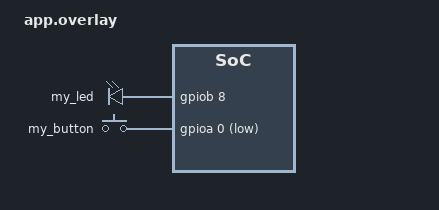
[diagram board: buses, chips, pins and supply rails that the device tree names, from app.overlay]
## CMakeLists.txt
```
cmake_minimum_required(VERSION 3.20.0)
set(BOARD stm32_min_dev/stm32f103xb CACHE STRING "Default board")

find_package(Zephyr REQUIRED HINTS $ENV{ZEPHYR_BASE})
project(zephyr-zl27arm)

list(APPEND CMAKE_MODULE_PATH ${ZEPHYR_BASE}/modules/nanopb)
include(nanopb)

target_include_directories(app PRIVATE src)
target_sources(app PRIVATE
        src/main_minimal.c
)
zephyr_nanopb_sources(app src/data.proto)
```

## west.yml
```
manifest:
  remotes:
    - name: zephyrproject-rtos
      url-base: https://github.com/zephyrproject-rtos

  projects:
    - name: zephyr
      remote: zephyrproject-rtos
      revision: v4.3.0
      import:
        name-allowlist:
          - cmsis_6
          - hal_stm32
          - segger
          - nanopb

  self:
    path: zephyr-zl27arm
```

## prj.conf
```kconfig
CONFIG_GPIO=y

CONFIG_NANOPB=y

# Debugging, tracing and logging settings
# (use the same for all projects)
CONFIG_STD_C23=y
#CONFIG_FPU=y
#CONFIG_ARM_MPU=y
#CONFIG_HW_STACK_PROTECTION=y

CONFIG_SERIAL=y
CONFIG_LOG=y
CONFIG_LOG_MODE_IMMEDIATE=y
CONFIG_LOG_DEFAULT_LEVEL=3

CONFIG_CONSOLE=y
CONFIG_LOG_BACKEND_RTT=y
CONFIG_USE_SEGGER_RTT=y

CONFIG_TRACING=y
CONFIG_TRACING_BACKEND_RAM=y
CONFIG_TRACING_GPIO=n
CONFIG_TRACING_SYSCALL=y
CONFIG_SEGGER_SYSTEMVIEW=y
CONFIG_SEGGER_SYSTEMVIEW_BOOT_ENABLE=n
CONFIG_SEGGER_SYSVIEW_RTT_BUFFER_SIZE=4096
CONFIG_SEGGER_SYSVIEW_POST_MORTEM_MODE=n

CONFIG_DEBUG=y
CONFIG_DEBUG_OPTIMIZATIONS=y
CONFIG_THREAD_ANALYZER=y
CONFIG_THREAD_NAME=y
```

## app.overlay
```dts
/ {
	aliases {
		led0 = &my_led;
		sw0 = &my_button;
	};

	leds {
		compatible = "gpio-leds";
		my_led: led_pb8 {
			gpios = <&gpiob 8 GPIO_ACTIVE_HIGH>;
		};
	};

	buttons {
		compatible = "gpio-keys";
		my_button: button_pa0 {
			gpios = <&gpioa 0 (GPIO_ACTIVE_LOW | GPIO_PULL_UP)>;
		};
	};
};
```

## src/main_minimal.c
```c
#include <zephyr/kernel.h>
#include <zephyr/drivers/gpio.h>
#include "zephyr/logging/log.h"

LOG_MODULE_REGISTER(main, LOG_LEVEL_INF);

static const struct gpio_dt_spec led =
    GPIO_DT_SPEC_GET(DT_ALIAS(led0), gpios);

static const struct gpio_dt_spec button =
    GPIO_DT_SPEC_GET(DT_ALIAS(sw0), gpios);

int is_led_enabled = false;

int main() {
    if (!gpio_is_ready_dt(&led) || !gpio_is_ready_dt(&button)) {
        return 0;
    }

    gpio_pin_configure_dt(&led, GPIO_OUTPUT_INACTIVE);
    gpio_pin_configure_dt(&button, GPIO_INPUT);

    while (true) {
        int value = gpio_pin_get_dt(&button);
        if (value == true) {
            is_led_enabled = !is_led_enabled;

            gpio_pin_set_dt(&led, is_led_enabled);
            LOG_INF("LED state changed: %d", is_led_enabled);

            k_msleep(250);
        }

        k_msleep(10); // Small debounce/delay
    }
    return 0;
}
```

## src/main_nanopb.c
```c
#include <zephyr/kernel.h>
#include <zephyr/logging/log.h>
#include <pb_encode.h>
#include <pb_decode.h>
#include "src/data.pb.h"

LOG_MODULE_REGISTER(main, LOG_LEVEL_INF);

void process_data(void) {
    uint8_t buffer[64];

    SensorData source_data = SensorData_init_zero;
    source_data.uptime = k_uptime_get_32();
    source_data.temperature = 24.5f;
    source_data.active = true;

    LOG_INF("Original: Uptime=%d, Temp=%.2f, Active=%d",
            source_data.uptime, (double)source_data.temperature, source_data.active);

    pb_ostream_t stream = pb_ostream_from_buffer(buffer, sizeof(buffer));
    bool status = pb_encode(&stream, SensorData_fields, &source_data);
    const size_t message_length = stream.bytes_written;

    if (!status) {
        LOG_ERR("Encoding failed: %s", PB_GET_ERROR(&stream));
        return;
    }

    LOG_HEXDUMP_INF(buffer, message_length, "Serialized Data");

    SensorData dest_data = SensorData_init_zero;
    pb_istream_t istream = pb_istream_from_buffer(buffer, message_length);
    status = pb_decode(&istream, SensorData_fields, &dest_data);

    if (!status) {
        LOG_ERR("Decoding failed: %s", PB_GET_ERROR(&istream));
        return;
    }

    LOG_INF("Decoded:  Uptime=%d, Temp=%.2f, Active=%d",
            dest_data.uptime, (double)dest_data.temperature, dest_data.active);
}

int main(void) {
    k_msleep(100);

    while (1) {
        process_data();
        k_msleep(5000);
    }
    return 0;
}
```

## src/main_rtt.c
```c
#include <zephyr/kernel.h>
#include <zephyr/drivers/gpio.h>
#include <zephyr/logging/log.h>
#include <zephyr/device.h>
#include <zephyr/drivers/spi.h>
#include <zephyr/tracing/tracing.h>

#include <SEGGER_SYSVIEW.h>

LOG_MODULE_REGISTER(main, LOG_LEVEL_INF);

static const struct gpio_dt_spec led =
    GPIO_DT_SPEC_GET(DT_ALIAS(led0), gpios);

static const struct gpio_dt_spec button =
    GPIO_DT_SPEC_GET(DT_ALIAS(sw0), gpios);

#define BUTTON_STATE_MARKER_ID  0
#define LED_STATE_MARKER_ID  1
#define LED_TOGGLE_CALCULATION_MARKER_ID  1

int is_led_enabled = false;

static SEGGER_SYSVIEW_DATA_REGISTER button_plot;
static SEGGER_SYSVIEW_DATA_REGISTER led_plot;

static void setup_plots() {
    button_plot.ID = BUTTON_STATE_MARKER_ID;
    button_plot.sName = "Button State";
    button_plot.DataType = SEGGER_SYSVIEW_TYPE_U32;
    button_plot.RangeMin = 0;
    button_plot.RangeMax = 4;
    button_plot.ScalingFactor = 1;
    button_plot.Offset = 0;
    SEGGER_SYSVIEW_RegisterData(&button_plot);

    led_plot.ID = LED_STATE_MARKER_ID;
    led_plot.sName = "LED State";
    led_plot.DataType = SEGGER_SYSVIEW_TYPE_U32;
    led_plot.RangeMin = 0;
    led_plot.RangeMax = 4;
    led_plot.ScalingFactor = 1;
    led_plot.Offset = 2;
    SEGGER_SYSVIEW_RegisterData(&led_plot);
}

int gpio_init(const struct gpio_dt_spec *gpio, const gpio_flags_t extra_flags) {
    // Check if GPIO exist
    if (!gpio_is_ready_dt(gpio)) {
        LOG_ERR("Error: GPIO device %s is not ready", gpio->port->name);
        return 1; // Indicate error
    } else {
        LOG_INF("GPIO device %s is ready", gpio->port->name);
    }

    // Init GPIO with extra flags
    const int ret = gpio_pin_configure_dt(gpio, extra_flags);
    if (ret < 0) {
        LOG_ERR("Error %d: failed to configure pin %d", ret, gpio->pin);
        return 1; // Indicate error
    } else {
        LOG_INF("Successfully configured pin %d", gpio->pin);
    }

    return ret;
}

int main(void)
{
    k_msleep(100);

    LOG_INF("System Starting via RTT...");
    SEGGER_SYSVIEW_Conf();

    SEGGER_SYSVIEW_NameMarker(LED_TOGGLE_CALCULATION_MARKER_ID, "LED toggle calculation");

    setup_plots();

    gpio_init(&led, GPIO_OUTPUT_ACTIVE);
    gpio_init(&button, GPIO_INPUT);

    int current_btn_val = -1;
    int last_btn_val = -1;

    // ReSharper disable once CppDFAEndlessLoop
    while (1) {
        current_btn_val = gpio_pin_get_dt(&button);

        if (current_btn_val != last_btn_val) {
            SEGGER_SYSVIEW_DATA_SAMPLE button_sample;
            button_sample.ID = BUTTON_STATE_MARKER_ID;
            button_sample.pValue.pU32 = (U32*) &current_btn_val;
            SEGGER_SYSVIEW_SampleData(&button_sample);

            last_btn_val = current_btn_val;
            SEGGER_SYSVIEW_PrintfHost("Button Processed: %d", current_btn_val);
        }

        if (current_btn_val == true) {
            SEGGER_SYSVIEW_OnUserStart(LED_TOGGLE_CALCULATION_MARKER_ID);
            is_led_enabled = !is_led_enabled;

            SEGGER_SYSVIEW_DATA_SAMPLE led_state_sample;
            led_state_sample.ID = LED_STATE_MARKER_ID;
            led_state_sample.pValue.pU32 = (U32*) &is_led_enabled;
            SEGGER_SYSVIEW_SampleData(&led_state_sample);

            gpio_pin_set_dt(&led, is_led_enabled);
            SEGGER_SYSVIEW_OnUserStop(LED_TOGGLE_CALCULATION_MARKER_ID);
            //LOG_INF("LED state changed: %d", is_led_enabled);

            k_msleep(250);
        }

        k_msleep(50);
    }
}
```

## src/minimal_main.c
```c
#include <zephyr/kernel.h>
#include <zephyr/drivers/gpio.h>
#include "zephyr/logging/log.h"

LOG_MODULE_REGISTER(main, LOG_LEVEL_INF);

static const struct gpio_dt_spec led =
    GPIO_DT_SPEC_GET(DT_ALIAS(led0), gpios);

static const struct gpio_dt_spec button =
    GPIO_DT_SPEC_GET(DT_ALIAS(sw0), gpios);

int main() {
    if (!gpio_is_ready_dt(&led) || !gpio_is_ready_dt(&button)) {
        return 0;
    }

    gpio_pin_configure_dt(&led, GPIO_OUTPUT_INACTIVE);
    gpio_pin_configure_dt(&button, GPIO_INPUT);

    while (true) {
        int value = gpio_pin_get_dt(&button);
        if (value == true) {
            is_led_enabled = !is_led_enabled;

            gpio_pin_set_dt(&led, is_led_enabled);
            LOG_INF("LED state changed: %d", is_led_enabled);

            k_msleep(250);
        }

        k_msleep(10); // Small debounce/delay
    }
    return 0;
}
```
